AUTOSAR XML (schema 00049)
package /HEVApps
  process design energy_mgmt_design: executable=energy_mgmt
  process design telemetry_design: executable=telemetry
package /HEVApps/exe
  executable energy_mgmt: category=APPLICATION_LEVEL, logging-behavior=USES-LOGGING, reporting-behavior=REPORTS-EXECUTION-STATE
    root sw component prototype energy_mgmt_root: application-type=EnergyManagementApp
  executable telemetry: category=APPLICATION_LEVEL, logging-behavior=USES-LOGGING, reporting-behavior=REPORTS-EXECUTION-STATE
    root sw component prototype telemetry_root: application-type=TelemetryApp
package /HEVApps/swc
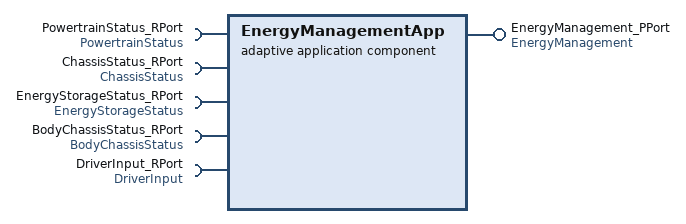
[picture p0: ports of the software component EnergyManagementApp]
  adaptive application sw component type EnergyManagementApp
    5 x require port:
      PowertrainStatus_RPort: required-interface=PowertrainStatus
      ChassisStatus_RPort: required-interface=ChassisStatus
      EnergyStorageStatus_RPort: required-interface=EnergyStorageStatus
      BodyChassisStatus_RPort: required-interface=BodyChassisStatus
      DriverInput_RPort: required-interface=DriverInput
    provide port EnergyManagement_PPort: provided-interface=EnergyManagement
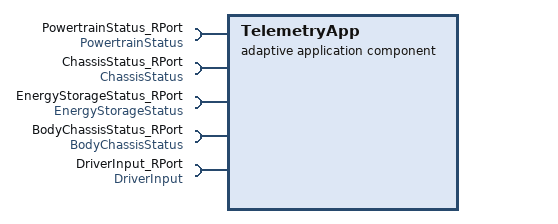
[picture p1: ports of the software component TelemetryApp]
  adaptive application sw component type TelemetryApp
    5 x require port:
      PowertrainStatus_RPort: required-interface=PowertrainStatus
      ChassisStatus_RPort: required-interface=ChassisStatus
      EnergyStorageStatus_RPort: required-interface=EnergyStorageStatus
      BodyChassisStatus_RPort: required-interface=BodyChassisStatus
      DriverInput_RPort: required-interface=DriverInput
